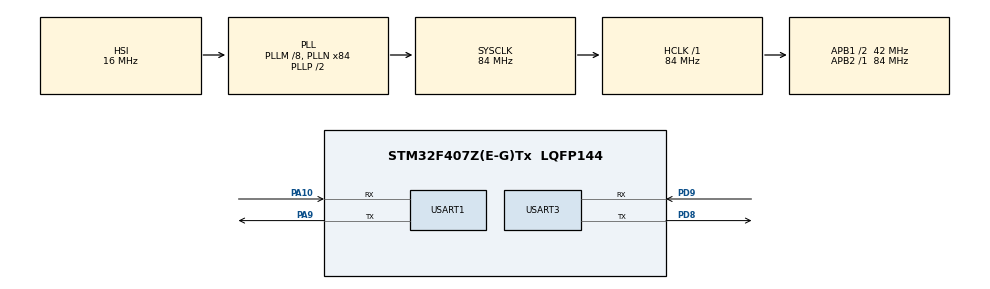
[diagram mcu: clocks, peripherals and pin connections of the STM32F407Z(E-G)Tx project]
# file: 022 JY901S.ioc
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Mcu.Family=STM32F4
Mcu.Name=STM32F407Z(E-G)Tx
Mcu.Package=LQFP144
NVIC.PriorityGroup=NVIC_PRIORITYGROUP_4
NVIC.TIM6_DAC_IRQn=true\:1\:0\:true\:false\:true\:true\:true\:true
NVIC.USART3_IRQn=true\:0\:0\:false\:false\:true\:true\:true\:true
PA10.Mode=Asynchronous
PA10.Signal=USART1_RX
PA13.Mode=Serial_Wire
PA13.Signal=SYS_JTMS-SWDIO
PA14.Mode=Serial_Wire
PA14.Signal=SYS_JTCK-SWCLK
PA9.Mode=Asynchronous
PA9.Signal=USART1_TX
PD8.Mode=Asynchronous
PD8.Signal=USART3_TX
PD9.Mode=Asynchronous
PD9.Signal=USART3_RX
PH0-OSC_IN.Mode=HSE-External-Oscillator
PH0-OSC_IN.Signal=RCC_OSC_IN
PH1-OSC_OUT.Mode=HSE-External-Oscillator
PH1-OSC_OUT.Signal=RCC_OSC_OUT
ProjectManager.HeapSize=0x200
ProjectManager.StackSize=0x400
ProjectManager.TargetToolchain=MDK-ARM V5.32
RCC.48MHZClocksFreq_Value=42000000
RCC.AHBFreq_Value=84000000
RCC.APB1CLKDivider=RCC_HCLK_DIV2
RCC.APB1Freq_Value=42000000
RCC.APB1TimFreq_Value=84000000
RCC.APB2Freq_Value=84000000
RCC.APB2TimFreq_Value=84000000
RCC.CortexFreq_Value=84000000
RCC.HCLKFreq_Value=84000000
RCC.HSE_VALUE=25000000
RCC.HSI_VALUE=16000000
RCC.LSE_VALUE=32768
RCC.PLLM=8
RCC.PLLN=84
RCC.SYSCLKFreq_VALUE=84000000
RCC.SYSCLKSource=RCC_SYSCLKSOURCE_PLLCLK
RCC.VCOOutputFreq_Value=168000000
TIM6.Period=1000-1
TIM6.Prescaler=840-1
USART1.VirtualMode=VM_ASYNC
USART3.VirtualMode=VM_ASYNC
VP_TIM6_VS_ClockSourceINT.Mode=Enable_Timer
board=custom

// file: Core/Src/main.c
/* USER CODE BEGIN Header */
/**
  ******************************************************************************
  * @file           : main.c
  * @brief          : Main program body
  ******************************************************************************
  * @attention
  *
  * Copyright (c) 2022 STMicroelectronics.
  * All rights reserved.
  *
  * This software is licensed under terms that can be found in the LICENSE file
  * in the root directory of this software component.
  * If no LICENSE file comes with this software, it is provided AS-IS.
  *
  ******************************************************************************
  */
/* USER CODE END Header */
#include "main.h"
#include "tim.h"
#include "usart.h"
#include "gpio.h"

/* USER CODE BEGIN Includes */
#include "jy901s.h"

/* USER CODE END Includes */

void SystemClock_Config(void);

/* USER CODE BEGIN 0 */
extern char ACCCALSW[5];//进入加速度校准模式
extern char SAVACALSW[5];//保存当前配置
extern char MAGNETICCALAM[5];      //磁力计校准
extern char SAVEMAGNETICCALAM[5];  //保存配置

extern uint8_t Rxdata;

/* USER CODE END 0 */

int main(void)
{

  /* MCU Configuration--------------------------------------------------------*/

  /* Reset of all peripherals, Initializes the Flash interface and the Systick. */
  HAL_Init();

  /* Configure the system clock */
  SystemClock_Config();

  /* Initialize all configured peripherals */
  MX_GPIO_Init();
  MX_TIM6_Init();
  MX_USART1_UART_Init();
  MX_USART3_UART_Init();
  /* USER CODE BEGIN 2 */

	HAL_TIM_Base_Start_IT(&htim6);
	HAL_UART_Receive_IT(&huart3,&Rxdata,1);

	sendcmd(ACCCALSW);HAL_Delay(100); //加速度计校准
	sendcmd(SAVACALSW);HAL_Delay(100);//保存当前配置

	sendcmd(MAGNETICCALAM);	HAL_Delay(100);   //磁力计校准
	sendcmd(SAVEMAGNETICCALAM);HAL_Delay(100);//保存当前配置

  /* USER CODE END 2 */

  /* Infinite loop */
  while (1)
  {

  }
}

void SystemClock_Config(void)
{
  RCC_OscInitTypeDef RCC_OscInitStruct = {0};
  RCC_ClkInitTypeDef RCC_ClkInitStruct = {0};

  /** Configure the main internal regulator output voltage
  */
  __HAL_RCC_PWR_CLK_ENABLE();
  __HAL_PWR_VOLTAGESCALING_CONFIG(PWR_REGULATOR_VOLTAGE_SCALE1);

  /** Initializes the RCC Oscillators according to the specified parameters
  * in the RCC_OscInitTypeDef structure.
  */
  RCC_OscInitStruct.OscillatorType = RCC_OSCILLATORTYPE_HSI;
  RCC_OscInitStruct.HSIState = RCC_HSI_ON;
  RCC_OscInitStruct.HSICalibrationValue = RCC_HSICALIBRATION_DEFAULT;
  RCC_OscInitStruct.PLL.PLLState = RCC_PLL_ON;
  RCC_OscInitStruct.PLL.PLLSource = RCC_PLLSOURCE_HSI;
  RCC_OscInitStruct.PLL.PLLM = 8;
  RCC_OscInitStruct.PLL.PLLN = 84;
  RCC_OscInitStruct.PLL.PLLP = RCC_PLLP_DIV2;
  RCC_OscInitStruct.PLL.PLLQ = 4;
  if (HAL_RCC_OscConfig(&RCC_OscInitStruct) != HAL_OK)
  {
    Error_Handler();
  }

  /** Initializes the CPU, AHB and APB buses clocks
  */
  RCC_ClkInitStruct.ClockType = RCC_CLOCKTYPE_HCLK|RCC_CLOCKTYPE_SYSCLK
                              |RCC_CLOCKTYPE_PCLK1|RCC_CLOCKTYPE_PCLK2;
  RCC_ClkInitStruct.SYSCLKSource = RCC_SYSCLKSOURCE_PLLCLK;
  RCC_ClkInitStruct.AHBCLKDivider = RCC_SYSCLK_DIV1;
  RCC_ClkInitStruct.APB1CLKDivider = RCC_HCLK_DIV2;
  RCC_ClkInitStruct.APB2CLKDivider = RCC_HCLK_DIV1;

  if (HAL_RCC_ClockConfig(&RCC_ClkInitStruct, FLASH_LATENCY_2) != HAL_OK)
  {
    Error_Handler();
  }
}

void Error_Handler(void)
{
  __disable_irq();
  while (1)
  {
  }
}
